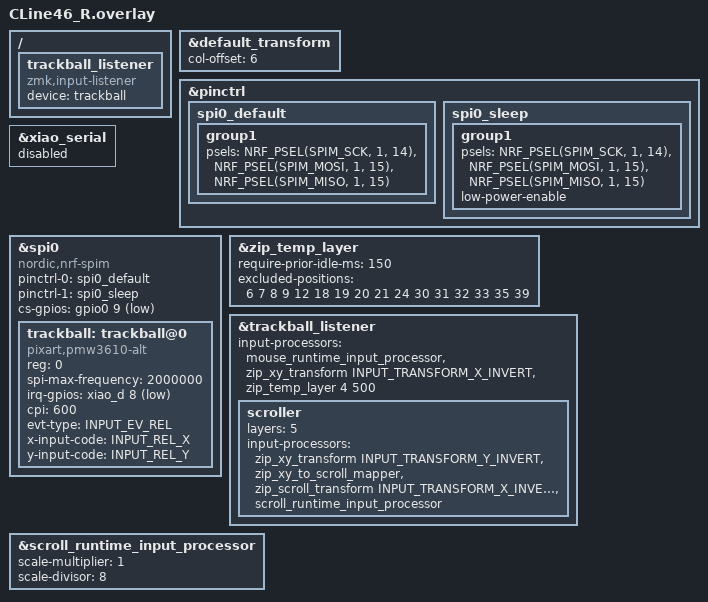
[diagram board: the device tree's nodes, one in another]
#include "CLine46.dtsi"
#include <zephyr/dt-bindings/input/input-event-codes.h>
#include <input/processors.dtsi>
#include <input/processors/runtime-input-processor.dtsi>
#include <behaviors/battery_history_request.dtsi>

&default_transform {
    col-offset = <6>;
};


/ {
    trackball_listener {
        status = "okay";
        compatible = "zmk,input-listener";
        device = <&trackball>;
    };
};

&pinctrl {
    spi0_default: spi0_default {
        group1 {
            psels = <NRF_PSEL(SPIM_SCK, 1, 14)>,
                <NRF_PSEL(SPIM_MOSI, 1, 15)>,
                <NRF_PSEL(SPIM_MISO, 1, 15)>;
        };
    };

    spi0_sleep: spi0_sleep {
        group1 {
            psels = <NRF_PSEL(SPIM_SCK, 1, 14)>,
                <NRF_PSEL(SPIM_MOSI, 1, 15)>,
                <NRF_PSEL(SPIM_MISO, 1, 15)>;
            low-power-enable;
        };
    };
};


&xiao_serial { status = "disabled"; };

&spi0 {
    status = "okay";
    compatible = "nordic,nrf-spim";
    pinctrl-0 = <&spi0_default>;
    pinctrl-1 = <&spi0_sleep>;
    pinctrl-names = "default", "sleep";
    cs-gpios = <&gpio0 9 GPIO_ACTIVE_LOW>;  //P0.09を指定(CS)

    trackball: trackball@0 {
        status = "okay";
        compatible = "pixart,pmw3610-alt";
        reg = <0>;
        spi-max-frequency = <2000000>;
        irq-gpios = <&xiao_d 8 (GPIO_ACTIVE_LOW | GPIO_PULL_UP)>;
        cpi = <600>;
        //swap-xy;
        evt-type = <INPUT_EV_REL>;
        x-input-code = <INPUT_REL_X>;
        y-input-code = <INPUT_REL_Y>;
    };
};

// === オートマウスレイヤー(BALL=4)の誤爆対策 ===
// zip_temp_layer 自体は移動量しきい値を持たないため、時間と打鍵で制御する。
&zip_temp_layer {
    // 直前の打鍵から 150ms 以内はボールを動かしても BALL 層へ入らない。
    // タイピング中に手がボールに触れたときの誤爆を防ぐ。
    require-prior-idle-ms = <150>;

    // ここに挙げた位置「以外」のキーを押すと BALL 層を即座に解除する。
    // = BALL 層で実際に使うキーだけを列挙 (位置番号は 0..45)。
    //    6  7  8  9      LC(W) 中クリック MB4 MB5
    //   18 19 20 21      ← 左クリック 右クリック →
    //   30 31 32 33      MO(SCROLL) スクロール下 スクロール上 LCTRL
    //   12 24 35         LCTRL / LSHIFT / RSHIFT (Ctrl+クリック等のため層を維持)
    //   39               左親指 td_lctl (hold=LCTRL)
    //   ※ 上記以外は BALL 層で &none か &trans。押した時点で BALL 層を抜ける。
    excluded-positions = <6 7 8 9 12 18 19 20 21 24 30 31 32 33 35 39>;
};

// Overrides for the input listener node
&trackball_listener {
    status = "okay";
    input-processors =<&mouse_runtime_input_processor>,
        //<&zip_xy_transform INPUT_TRANSFORM_Y_INVERT>;         //Y軸反転
        //<&zip_xy_transform INPUT_TRANSFORM_XY_SWAP>,        //X軸とY軸の入れ替え
        <&zip_xy_transform INPUT_TRANSFORM_X_INVERT>,       //X軸反転
        <&zip_temp_layer 4 500>;                            //ボール移動で BALL(4) 層へ / 停止後 500ms で復帰


    scroller {
        layers = <5>;                                       //SCROLL 層
        input-processors = 
            // <&zip_xy_transform INPUT_TRANSFORM_XY_SWAP>,        //X軸とY軸の入れ替え
            // <&zip_xy_transform INPUT_TRANSFORM_X_INVERT>,       //X軸反転
            <&zip_xy_transform INPUT_TRANSFORM_Y_INVERT>,       //Y軸反転
            <&zip_xy_to_scroll_mapper>,                         //スクロールモードに変更
            <&zip_scroll_transform INPUT_TRANSFORM_X_INVERT>,   //スクロールのX軸反転
            //<&zip_scroll_transform INPUT_TRANSFORM_Y_INVERT>,   //スクロールのY軸反転
            <&scroll_runtime_input_processor>;                  //スクロール量・軸スナップをDYA Studioから調整可能に
    };
};

// スクロール用のランタイム入力プロセッサ。
//
// 従来の <&zip_scroll_scaler 1 8> を置き換えたもの。scaler は再ビルドしないと
// 変更できなかったが、これに替えるとスクロール量を DYA Studio の
// 「トラックボール設定」から調整できるようになる。あわせて軸スナップ
// (移動を縦横どちらかに固定する機能。表計算ソフトなどで有用) も利用できる。
//
// 注意: このノードは runtime-input-processor.dtsi 内で /omit-if-no-ref/ 指定
// されているため、ここで参照して初めて firmware に組み込まれる。参照が無いと
// DYA Studio のプロセッサ一覧にも現れない。
//
// 下の初期値は従来の <&zip_scroll_scaler 1 8> と同じ 1/8 倍。
// 一度 DYA Studio で変更すると、そちらが保存されて以後優先される。
&scroll_runtime_input_processor {
    scale-multiplier = <1>;
    scale-divisor = <8>;
};
